# dut: IP-XACT component
VLNV Origen:Origen:dut:

## Address spaces and blocks
RegisterMap.: base 0x0, range 20, width 32
RegisterMap.atx: base 0x40000000, range 8, width 32
RegisterMap.rf1: base 0x1000, range 8, width 32
RegisterMap.rf2: base 0x2000, range 8, width 32

## Registers
Registers are 8-bit, read-write, reset 0x0 unless marked. A register's access mark holds for its fields unless they carry their own. Offsets are from the block's base; lines under a group give offsets from that group; [hi:lo] are bit positions; {n}, {i} and the like mark numbered series; 'fields as' and 'values as' point back to an identical list; <NAME> marks a mode.

## RegisterMap.block0
Base 0x00000000
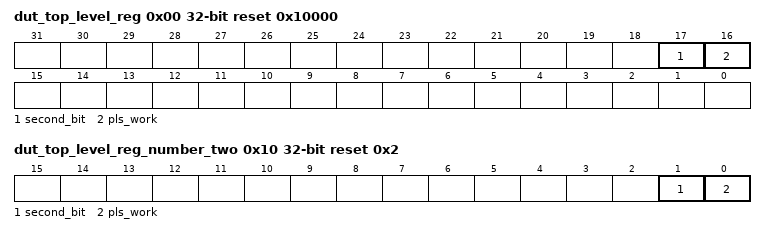
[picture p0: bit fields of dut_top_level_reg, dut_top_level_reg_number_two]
0x00 dut_top_level_reg 32-bit reset 0x10000
  [17] second_bit, [16] pls_work
0x10 dut_top_level_reg_number_two 32-bit reset 0x2
  [1] second_bit, [0] pls_work ro

## RegisterMap.atx
Base 0x40000000
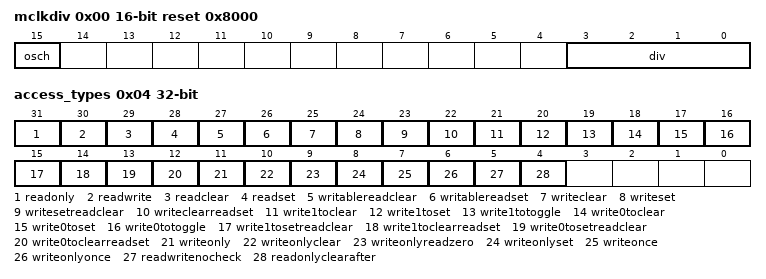
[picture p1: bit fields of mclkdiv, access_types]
0x00 mclkdiv 16-bit reset 0x8000 — MPU Clock Divider Register
  [15] osch — Oscillator (Hi)
    0=Clock is the externally supplied bus clock bus_clk; 1=Clock is the internal oscillator from the hardblock
  [3:0] div — Divider Value
0x04 access_types 32-bit — Access Type Test Register
  [31] readonly ro, [30] readwrite, [29] readclear rc, [28] readset rs, [27] writablereadclear wrc, [26] writablereadset wrs, [25] writeclear wc, [24] writeset ws, [23] writesetreadclear wsrc, [22] writeclearreadset wcrs, [21] write1toclear w1c, [20] write1toset w1s, [19] write1totoggle w1t, [18] write0toclear w0c, [17] write0toset w0s, [16] write0totoggle w0t, [15] write1tosetreadclear w1src, [14] write1toclearreadset w1crs, [13] write0tosetreadclear w0src, [12] write0toclearreadset w0crs, [11] writeonly wo, [10] writeonlyclear woc, [9] writeonlyreadzero worz, [8] writeonlyset wos, [7] writeonce w1, [6] writeonlyonce wo1, [5] readwritenocheck dc, [4] readonlyclearafter rowz

## RegisterMap.rf1
Base 0x00001000
0x00 reg0 ro
0x01 reg1
  [7:0] reg1_f
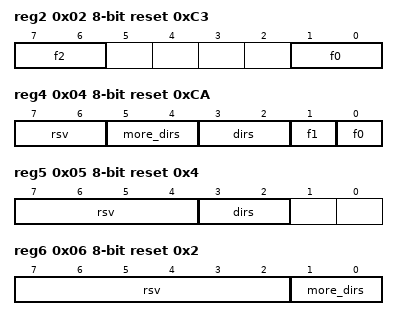
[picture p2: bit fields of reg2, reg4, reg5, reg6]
0x02 reg2 reset 0xC3
  [7:6] f2, [1:0] f0
0x03 reg3 reset 0x38
  [5:3] f0
0x04 reg4 reset 0xCA
  [7:6] rsv, [5:4] more_dirs ro, [3:2] dirs wo, [1] f1, [0] f0
0x05 reg5 reset 0x4
  [7:4] rsv, [3:2] dirs
0x06 reg6 ro reset 0x2
  [7:2] rsv, [1:0] more_dirs

## RegisterMap.rf2
Base 0x00002000
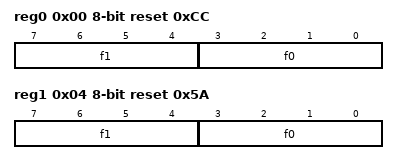
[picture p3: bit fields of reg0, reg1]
0x00 reg0 reset 0xCC
  [7:4] f1, [3:0] f0
0x04 reg1 reset 0x5A
  [7:4] f1, [3:0] f0
